# MINI51XAE_v1 register map
File version: 1.0
Registers are 32-bit, read-write, reset 0x0 unless marked. A register's access mark holds for its fields unless they carry their own. Offsets are from the block's base; [hi:lo] are bit positions; {n}, {i} and the like mark numbered series; 'fields as' and 'values as' point back to an identical list.

## ADC — ADC Register Map
Base 0x400E0000
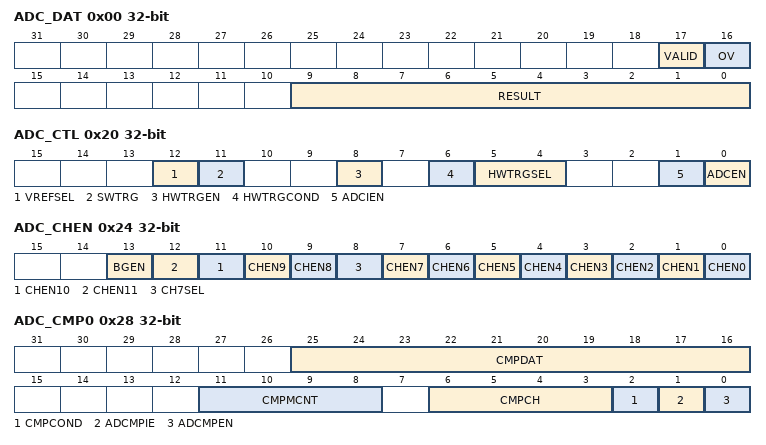
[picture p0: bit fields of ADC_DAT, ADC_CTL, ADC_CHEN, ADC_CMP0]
0x00 ADC_DAT ro — ADC Data Register
  [17] VALID — Valid Flag. This bit is set to 1 when ADC conversion is completed and cleared by hardware after the ADC_DAT register is read.
    0=Data in RESULT[9:0] bits not valid; 1=Data in RESULT[9:0] bits valid
  [16] OV — Over Run Flag. If converted data in RESULT[9:0] has not been read before the new conversion result is loaded to this register, OV is set to 1. It is cleared by hardware after the ADC_DAT register is read.
    0=Data in RESULT[9:0] is recent conversion result; 1=Data in RESULT[9:0] overwrote
  [9:0] RESULT — A/D Conversion Result. This field contains conversion result of ADC.
0x20 ADC_CTL — ADC Control Register
  [12] VREFSEL — Reference Voltage Selection Signal
    0=Connect VDD5V to internal reference; 1=Connect VREF (AIN0) pin to internal reference
  [11] SWTRG — A/D Conversion Start. SWTRG bit can be set to 1 from two sources: software and external pin STADC. SWTRG will be cleared to 0 by hardware automatically after conversion complete.
    0=Conversion stopped and A/D converter entered idle state; 1=Conversion start
  [8] HWTRGEN — External Trigger Enable. Enable or disable triggering of A/D conversion by external STADC pin. If external trigger is enabled, the SWTRG bit can be set to 1 by the selected hardware trigger source.
    0=External trigger Disabled; 1=External trigger Enabled
  [6] HWTRGCOND — External Trigger Condition. This bit decides whether the external pin STADC trigger event is falling or raising edge. The signal must be kept at stable state at least 4 PCLKs at high and low state for edge trigger.
    0=Falling edge; 1=Raising edge
  [5:4] HWTRGSEL — Hardware Trigger Source. Note: Software should disable HWTRGEN and SWTRG before change HWTRGSEL.
    0=A/D conversion is started by external STADC pin; 3=A/D conversion is started by PWM trigger
  [1] ADCIEN — A/D Interrupt Enable. A/D conversion end interrupt request is generated if ADCIEN bit is set to 1.
    0=A/D interrupt function Disabled; 1=A/D interrupt function Enabled
  [0] ADCEN — A/D Converter Enable. Note: Before starting A/D conversion function, this bit should be set to 1. Clear it to 0 to disable A/D converter analog circuit to save power consumption.
    0=A/D Converter Disabled; 1=A/D Converter Enabled
0x24 ADC_CHEN — ADC Channel Enable Register
  [13] BGEN — Band-Gap Voltage Measurement. Note: User can set BGEN high to use ADC to measure Band-Gap voltage directly to instead of enabling PRESET and CHEN7.
    0=Disabled; 1=Enabled
  [n+1] CHEN{n} (n=8..11) — Analog Input Channel {n} Enable
    0=Disabled; 1=Enabled
  [8] CH7SEL — Analog Input Channel 7 Selection. Note: When software selects the band-gap voltage as the analog input source of ADC channel 7, the ADC clock rate needs to be limited to lower than 300 kHz.
    0=External analog input; 1=Internal band-gap voltage (VBG)
  [n] CHEN{n} (n=1..7) — Analog Input Channel {n} Enable
    0=Channel {n} Disabled; 1=Channel {n} Enabled
  [0] CHEN0 — Analog Input Channel 0 Enable. Note: If software enables more than one channel, the channel with the smallest number will be selected and the other enabled channels will be ignored.
    0=Channel 0 Disabled; 1=Channel 0 Enabled
0x28 ADC_CMP0 — ADC Compare Register 0
  [25:16] CMPDAT — Comparison Data. The 10-bit data is used to compare with conversion result of specified channel.
  [11:8] CMPMCNT — Compare Match Count. When the specified A/D channel analog conversion result matches the compare condition defined by CMPCOND[2], the internal match counter will increase 1. When the internal counter reaches the value to (CMPMCNT +1), the ADCMPFx bit will be set.
  [6:3] CMPCH — Compare Channel Selection
    {v}=Channel {v} conversion result is selected to be compared (v=0..11); 12=band-gap voltage result is selected to be compared
  [2] CMPCOND — Compare Condition. Note: When the internal counter reaches the value to (CMPMCNT +1), the ADCMPFx bit will be set.
    0=Set the compare condition as that when a 10-bit A/D conversion result is less than the 10-bit CMPDAT (ADCMPRx[25:16]), the internal match counter will increase one; 1=Set the compare condition as that when a 10-bit A/D conversion result is greater or equal to the 10-bit CMPDAT (ADCMPRx[25:16]), the internal match counter will increase one
  [1] ADCMPIE — Compare Interrupt Enable. If the compare function is enabled and the compare condition matches the setting of CMPCOND and CMPMCNT, ADCMPFx bit will be asserted, in the meanwhile, if CMPCOND is set to 1, a compare interrupt request is generated.
    0=Compare function interrupt Disabled; 1=Compare function interrupt Enabled
  [0] ADCMPEN — Compare Enable. Set 1 to this bit to enable comparing CMPDAT[9:0] with specified channel conversion results when converted data is loaded into the ADC_DAT register.
    0=Compare function Disabled; 1=Compare function Enabled
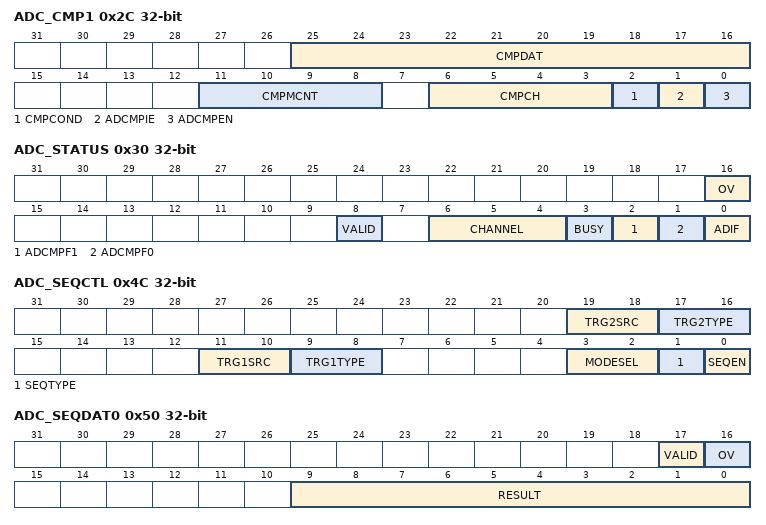
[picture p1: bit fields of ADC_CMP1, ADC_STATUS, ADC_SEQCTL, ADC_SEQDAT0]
0x2C ADC_CMP1 — ADC Compare Register 1
  fields as ADC_CMP0
0x30 ADC_STATUS
  [16] OV ro — OV Flag (Read Only). It is a mirror to OV bit in ADC_DAT register.
  [8] VALID ro — Data Valid Flag (Read Only). It is a mirror of VALID bit in ADC_DAT register.
  [6:4] CHANNEL ro — Current Conversion Channel (Read Only)
  [3] BUSY ro — BUSY/IDLE (Read Only). This bit is mirror of as SWTRG bit in ADC_CTL
    0=A/D converter is in idle state; 1=A/D converter is busy at conversion
  [2] ADCMPF1 — Compare Flag 1. When the selected channel A/D conversion result meets the setting condition in ADC_CMP1, this bit is set to 1. Software can write 1 to clear this bit to zero.
    0=Conversion result in ADC_DAT does not meet the ADC_CMP1 setting; 1=Conversion result in ADC_DAT meets the ADC_CMP1 setting
  [1] ADCMPF0 — Compare Flag 0. When the selected channel A/D conversion result meets the setting condition in ADC_CMP0, this bit is set to 1. Software can write 1 to clear this bit to zero.
    0=Conversion result in ADC_DAT does not meet the ADC_CMP0 setting; 1=Conversion result in ADC_DAT meets the ADC_CMP0 setting
  [0] ADIF — A/D Conversion End Flag. A status flag that indicates the end of A/D conversion. ADIF is set to 1 When A/D conversion ends. Software can write 1 to clear this bit to zero.
0x44 ADC_TRGDLY — ADC Trigger Delay Control Register
  [7:0] DELAY — PWM Trigger Delay Timer. Set this field will delay ADC start conversion time after PWM trigger. PWM trigger delay time is (4 * DELAY) * system clock.
0x48 ADC_EXTSMPT — ADC Sampling Time Counter Register
  [3:0] EXTSMPT — ADC Sampling Counter. ADC sampling counters are 6 ADC clock is suggestion.
    0=6 ADC Clock; 1=7 ADC Clock; 2=8 ADC Clock; 3=10 ADC Clock; 4=14 ADC Clock; 5=22 ADC Clock; 6=38 ADC Clock; 7=70 ADC Clock; 8=1346 ADC Clock; 9=262 ADC Clock; 10=518 ADC Clock; {v}=1030 ADC Clock (v=11..15)
0x4C ADC_SEQCTL — ADC PWM Sequential Mode Control Register
  [19:18] TRG2SRC — ADC Sequential Mode Trigger2 Source
    0=PWM0; 1=PWM2; 2=PWM4
  [17:16] TRG2TYPE — ADC Sequential Mode Trigger2 Type
    0=Rising of the selected PWM; 1=Center of the selected PWM; 2=Falling of the selected PWM; 3=Period of the selected PWM
  [11:10] TRG1SRC — ADC Sequential Mode Trigger1 Source
    0=PWM0; 1=PWM2; 2=PWM4
  [9:8] TRG1TYPE — ADC Sequential Mode Trigger1 Type
    values as TRG2TYPE
  [3:2] MODESEL — ADC Sequential Mode Selection
    0=Issue ADC_INT after Channel 0 then Channel 1 conversion finishes when SEQEN =1; 1=Issue ADC_INT after Channel 1 then Channel 2 conversion finishes when SEQEN =1; 2=Issue ADC_INT after Channel 0 then Channel 2 conversion finishes when SEQEN =1
  [1] SEQTYPE — ADC Sequential Mode Type
    0=ADC delay time is only inserted before the first conversion. The second conversion starts immediately after the first conversion is completed. (for 2/3-shunt type); 1=ADC delay time is inserted before each conversion. (for 1-shunt type)
  [0] SEQEN — ADC Sequential Mode Enable. When ADC sequential mode is enabled, two of three ADC channels from 0 to 2 will automatically convert analog data in the sequence of channel [0, 1] or channel[1, 2] or channel[0, 2] defined by SEQ_MODE[1:0].
    0=ADC sequential mode Disabled; 1=ADC sequential mode Enabled
0x50 ADC_SEQDAT0 ro — ADC PWM Sequential Mode Result Register 0
  [17] VALID — Valid Flag. This bit is set to 1 when ADC conversion is completed and cleared by hardware after the ADC_DAT register is read.
    0=Data in RESULT [9:0] bits not valid; 1=Data in RESULT. ADC_TRGDLY [9:0] bits valid
  [16] OV — Over Run Flag. If converted data in RESULT [9:0] has not been read before the new conversion result is loaded to this register, OV is set to 1. It is cleared by hardware after the ADC_DAT register is read.
    0=Data in RESULT [9:0] is recent conversion result; 1=Data in RESULT [9:0] overwritten
  [9:0] RESULT — A/D PWM Sequential Mode Conversion Result. This field contains conversion result of ADC.
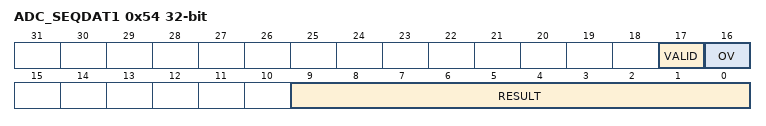
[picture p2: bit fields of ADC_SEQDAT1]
0x54 ADC_SEQDAT1 ro — ADC PWM Sequential Mode Result Register 1
  fields as ADC_SEQDAT0
